# NUC100CN_v1 register map
File version: 1.0
NUC100CN_v1 SVD file
Registers are 32-bit, read-write, reset 0x0 unless marked. A register's access mark holds for its fields unless they carry their own. Offsets are from the block's base; lines under a group give offsets from that group; [hi:lo] are bit positions; {n}, {i} and the like mark numbered series; 'fields as' and 'values as' point back to an identical list; <NAME> marks a mode.

## Memory map
0x40004000 WDT size 0x4 — WDT Register Map
0x40008000 RTC size 0x34 — RTC Register Map
0x40010000 TMR01 blocks up to offset 0x3C — TMR Register Map
0x40020000 I2C0 size 0x34 — I2C Register Map
0x40030000 SPI0 blocks up to offset 0x40 — SPI Register Map
0x40034000 SPI1 blocks up to offset 0x40 — SPI Register Map
0x40040000 PWMA blocks up to offset 0x80 — PWM Register Map
0x40050000 UART0 size 0x34 — UART Register Map
0x40060000 USB blocks up to offset 0x94 — USB Register Map
0x400D0000 CMP size 0xC — CMP Register Map
0x400E0000 ADC blocks up to offset 0x44 — ADC Register Map
0x40100000 PS2 size 0x20 — PS2 Register Map
0x40110000 TMR23 blocks up to offset 0x3C — TMR Register Map
0x40120000 I2C1 size 0x34 — I2C Register Map
0x40130000 SPI2 blocks up to offset 0x40 — SPI Register Map
0x40134000 SPI3 blocks up to offset 0x40 — SPI Register Map
0x40140000 PWMB blocks up to offset 0x80 — PWM Register Map
0x40150000 UART1 size 0x34 — UART Register Map
0x40154000 UART2 size 0x34 — UART Register Map
0x40180000 CAN0 blocks up to offset 0x170 — CAN Register Map
0x401A0000 I2S size 0x18 — I2S Register Map
0x50000000 GCR blocks up to offset 0x104 — GCR Register Map
0x50000200 CLK size 0x28 — CLK Register Map
0x50000300 INT size 0x88 — INT Register Map
0x50004000 GP blocks up to offset 0x340 — GP Register Map
{0x50008000+0x100*n} PDMA_ch{n} blocks up to offset 0x84 (n=0..8) — PDMA Register Map
0x50008F00 PDMA_GCR size 0x14 — PDMA Register Map
0x5000C000 FMC size 0x1C — FMC Register Map
0x50010000 EBI size 0x8 — EBI Register Map
0xE000E000 SCS blocks up to offset 0xD24 — SCS Register Map

## I2C0 — I2C Register Map
Base 0x40020000
Same registers: I2C1 0x40120000
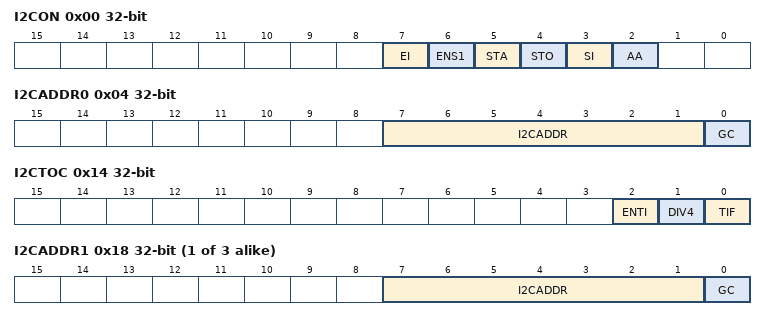
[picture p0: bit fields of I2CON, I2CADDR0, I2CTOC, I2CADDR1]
0x00 I2CON — I2C Control Register
  [7] EI — Interrupt Enable
    0=I2C interrupt Disabled; 1=I2C interrupt Enabled
  [6] ENS1 — I2C Controller Enable Bit
    0=Disabled; 1=Enabled
  [5] STA — I2C START Control Bit. Setting STA to logic 1 to enter Master mode, the I2C hardware sends a START or repeat START condition to bus when the bus is free.
  [4] STO — I2C STOP Control Bit. In Master mode, setting STO to transmit a STOP condition to bus then I2C hardware will check the bus condition if a STOP condition is detected this bit will be cleared by hardware automatically. In a Slave mode, setting STO resets I2C hardware to the defined "not addressed" Slave mode. This means it is NO LONGER in the slave receiver mode to receive data from the master transmit device.
  [3] SI — I2C Interrupt Flag. When a new I2C state is present in the I2CSTATUS register, the SI flag is set by hardware, and if bit EI (I2CON [7]) is set, the I2C interrupt is requested. SI must be cleared by software. Clear SI is by writing 1 to this bit.
  [2] AA — Assert Acknowledge Control Bit
0x04 I2CADDR0 — I2C Slave Address Register0
  [7:1] I2CADDR — I2C Address Register. The content of this register is irrelevant when I2C is in Master mode. In the Slave mode, the seven most significant bits must be loaded with the chip's own address. The I2C hardware will react if either of the address is matched.
  [0] GC — General Call Function
    0=General Call function Disabled; 1=General Call function Enabled
0x08 I2CDAT — I2C Data Register
  [7:0] I2CDAT — I2C Data Register. Bit [7:0] is located with the 8-bit transferred data of I2C serial port.
0x0C I2CSTATUS ro reset 0xF8
  [7:0] I2CSTATUS — I2C Status Register. The status register of I2C:
0x10 I2CLK — I2C Clock Divided Register
  [7:0] I2CLK — I2C clock divided Register. Note: The minimum value of I2CLK is 4.
0x14 I2CTOC — I2C Time-out Counter Register
  [2] ENTI — Time-out Counter Enable/Disable. When Enabled, the 14-bit time-out counter will start counting when SI is clear. Setting flag SI to high will reset counter and re-start up counting after SI is cleared.
    0=Disabled; 1=Enabled
  [1] DIV4 — Time-Out counter input clock is divided by 4. When Enabled, The time-out period is extend 4 times.
    0=Disabled; 1=Enabled
  [0] TIF — Time-Out Flag. This bit is set by H/W when I2C time-out happened and it can interrupt CPU if I2C interrupt enable bit (EI) is set to 1. Software can write 1 to clear this bit.
{0x14+4i} I2CADDR{i} (i=1..3) — I2C Slave Address Register{i}
  fields as I2CADDR0
{0x24+4i} I2CADM{i} (i=0..3) — I2C Slave Address Mask Register{i}
  [7:1] I2CADM — I2C Address Mask register. I2C bus controllers support multiple address recognition with four address mask register. When the bit in the address mask register is set to one, it means the received corresponding address bit is don't-care. If the bit is set to 0, that means the received corresponding register bit should be exact the same as address register.
    0=Mask disable (the received corresponding register bit should be exact the same as address register.); 1=Mask enable (the received corresponding address bit is don't care.)
